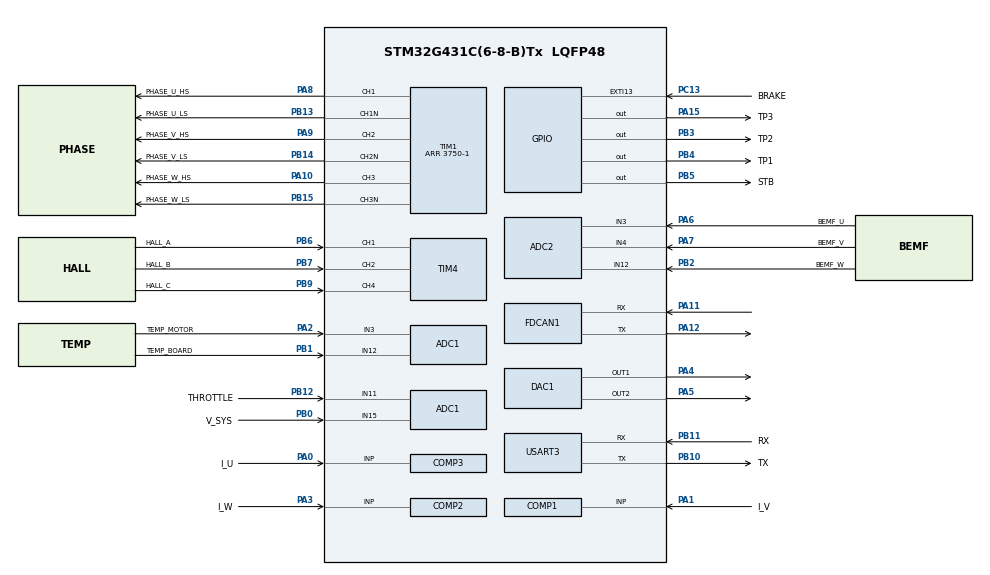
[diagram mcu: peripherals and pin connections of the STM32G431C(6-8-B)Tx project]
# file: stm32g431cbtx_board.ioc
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ADC1.Channel-0\#ChannelRegularConversion=ADC_CHANNEL_1
ADC1.Channel-1\#ChannelRegularConversion=ADC_CHANNEL_2
ADC1.Channel-2\#ChannelRegularConversion=ADC_CHANNEL_4
ADC1.Channel-3\#ChannelRegularConversion=ADC_CHANNEL_11
ADC1.Channel-4\#ChannelRegularConversion=ADC_CHANNEL_12
ADC1.Channel-5\#ChannelRegularConversion=ADC_CHANNEL_15
ADC1.Channel-6\#ChannelRegularConversion=ADC_CHANNEL_3
ADC1.ClockPrescaler=ADC_CLOCK_SYNC_PCLK_DIV4
ADC1.DMAContinuousRequests=ENABLE
ADC1.ExternalTrigConv=ADC_EXTERNALTRIG_T1_TRGO
ADC1.ExternalTrigConvEdge=ADC_EXTERNALTRIGCONVEDGE_FALLING
ADC1.NbrOfConversion=7
ADC1.NbrOfConversionFlag=1
ADC1.OffsetNumber-0\#ChannelRegularConversion=ADC_OFFSET_NONE
ADC1.OffsetNumber-1\#ChannelRegularConversion=ADC_OFFSET_NONE
ADC1.OffsetNumber-2\#ChannelRegularConversion=ADC_OFFSET_NONE
ADC1.OffsetNumber-3\#ChannelRegularConversion=ADC_OFFSET_NONE
ADC1.OffsetNumber-4\#ChannelRegularConversion=ADC_OFFSET_NONE
ADC1.OffsetNumber-5\#ChannelRegularConversion=ADC_OFFSET_NONE
ADC1.OffsetNumber-6\#ChannelRegularConversion=ADC_OFFSET_NONE
ADC1.Rank-0\#ChannelRegularConversion=1
ADC1.Rank-1\#ChannelRegularConversion=2
ADC1.Rank-2\#ChannelRegularConversion=3
ADC1.Rank-3\#ChannelRegularConversion=4
ADC1.Rank-4\#ChannelRegularConversion=5
ADC1.Rank-5\#ChannelRegularConversion=6
ADC1.Rank-6\#ChannelRegularConversion=7
ADC1.SamplingTime-0\#ChannelRegularConversion=ADC_SAMPLETIME_6CYCLES_5
ADC1.SamplingTime-1\#ChannelRegularConversion=ADC_SAMPLETIME_6CYCLES_5
ADC1.SamplingTime-2\#ChannelRegularConversion=ADC_SAMPLETIME_6CYCLES_5
ADC1.SamplingTime-3\#ChannelRegularConversion=ADC_SAMPLETIME_6CYCLES_5
ADC1.SamplingTime-4\#ChannelRegularConversion=ADC_SAMPLETIME_6CYCLES_5
ADC1.SamplingTime-5\#ChannelRegularConversion=ADC_SAMPLETIME_6CYCLES_5
ADC1.SamplingTime-6\#ChannelRegularConversion=ADC_SAMPLETIME_6CYCLES_5
ADC1.master=1
ADC2.Channel-0\#ChannelRegularConversion=ADC_CHANNEL_3
ADC2.ClockPrescaler=ADC_CLOCK_SYNC_PCLK_DIV4
ADC2.NbrOfConversionFlag=1
ADC2.OffsetNumber-0\#ChannelRegularConversion=ADC_OFFSET_NONE
ADC2.Rank-0\#ChannelRegularConversion=1
ADC2.SamplingTime-0\#ChannelRegularConversion=ADC_SAMPLETIME_2CYCLES_5
DAC1.DAC_Channel-DAC_OUT2_ExtAndInt=DAC_CHANNEL_2
DAC3.DAC_Channel-DAC_OUT2_Int=DAC_CHANNEL_2
Dma.ADC1.0.Direction=DMA_PERIPH_TO_MEMORY
Dma.ADC1.0.EventEnable=DISABLE
Dma.ADC1.0.Instance=DMA1_Channel1
Dma.ADC1.0.MemDataAlignment=DMA_MDATAALIGN_WORD
Dma.ADC1.0.MemInc=DMA_MINC_ENABLE
Dma.ADC1.0.Mode=DMA_CIRCULAR
Dma.ADC1.0.PeriphDataAlignment=DMA_PDATAALIGN_WORD
Dma.ADC1.0.PeriphInc=DMA_PINC_DISABLE
Dma.ADC1.0.Polarity=HAL_DMAMUX_REQ_GEN_RISING
Dma.ADC1.0.Priority=DMA_PRIORITY_LOW
Dma.ADC1.0.RequestNumber=1
Dma.ADC1.0.SignalID=NONE
Dma.ADC1.0.SyncEnable=DISABLE
Dma.ADC1.0.SyncPolarity=HAL_DMAMUX_SYNC_NO_EVENT
Dma.ADC1.0.SyncRequestNumber=1
Dma.ADC1.0.SyncSignalID=NONE
Dma.Request0=ADC1
FDCAN1.AutoRetransmission=ENABLE
FDCAN1.NominalPrescaler=20
FDCAN1.NominalTimeSeg1=12
FDCAN1.StdFiltersNbr=1
FDCAN1.TransmitPause=ENABLE
Mcu.Family=STM32G4
Mcu.Name=STM32G431C(6-8-B)Tx
Mcu.Package=LQFP48
NVIC.DMA1_Channel1_IRQn=true\:0\:0\:false\:false\:true\:false\:true\:true
NVIC.EXTI15_10_IRQn=true\:0\:0\:false\:false\:false\:true\:false\:true
NVIC.FDCAN1_IT0_IRQn=true\:0\:0\:false\:false\:true\:true\:true\:true
NVIC.PriorityGroup=NVIC_PRIORITYGROUP_4
NVIC.TIM1_BRK_TIM15_IRQn=true\:0\:0\:false\:false\:false\:true\:true\:true
NVIC.TIM2_IRQn=true\:0\:0\:false\:false\:false\:true\:true\:true
NVIC.TIM3_IRQn=true\:0\:0\:false\:false\:false\:true\:true\:true
NVIC.TIM4_IRQn=true\:0\:0\:false\:false\:false\:true\:true\:true
NVIC.TIM8_UP_IRQn=true\:0\:0\:false\:false\:false\:true\:true\:true
PA0.GPIO_Label=I_U
PA0.Signal=SharedAnalog_PA0
PA1.GPIO_Label=I_V
PA1.Signal=SharedAnalog_PA1
PA10.GPIO_Label=PHASE_W_HS
PA10.Signal=S_TIM1_CH3
PA11.Mode=FDCAN_Activate
PA11.Signal=FDCAN1_RX
PA12.Mode=FDCAN_Activate
PA12.Signal=FDCAN1_TX
PA13.Mode=Serial_Wire
PA13.Signal=SYS_JTMS-SWDIO
PA14.Mode=Serial_Wire
PA14.Signal=SYS_JTCK-SWCLK
PA15.GPIO_Label=TP3
PA15.GPIO_Speed=GPIO_SPEED_FREQ_VERY_HIGH
PA15.Signal=GPIO_Output
PA2.GPIO_Label=TEMP_MOTOR
PA2.Mode=IN3-Single-Ended
PA2.Signal=ADC1_IN3
PA3.GPIO_Label=I_W
PA3.Signal=SharedAnalog_PA3
PA4.Signal=COMP_DAC11_group
PA5.Signal=COMP_DAC12_group
PA6.GPIO_Label=BEMF_U
PA6.Mode=IN3-Single-Ended
PA6.Signal=ADC2_IN3
PA7.GPIO_Label=BEMF_V
PA7.Mode=IN4-Single-Ended
PA7.Signal=ADC2_IN4
PA8.GPIO_Label=PHASE_U_HS
PA8.Signal=S_TIM1_CH1
PA9.GPIO_Label=PHASE_V_HS
PA9.Signal=S_TIM1_CH2
PB0.GPIO_Label=V_SYS
PB0.Signal=SharedAnalog_PB0
PB1.GPIO_Label=TEMP_BOARD
PB1.Mode=IN12-Single-Ended
PB1.Signal=ADC1_IN12
PB10.GPIO_Label=TX
PB10.Mode=Asynchronous
PB10.Signal=USART3_TX
PB11.GPIO_Label=RX
PB11.Mode=Asynchronous
PB11.Signal=USART3_RX
PB12.GPIO_Label=THROTTLE
PB12.Mode=IN11-Single-Ended
PB12.Signal=ADC1_IN11
PB13.GPIO_Label=PHASE_U_LS
PB13.Mode=PWM Generation1 CH1 CH1N
PB13.Signal=TIM1_CH1N
PB14.GPIO_Label=PHASE_V_LS
PB14.Mode=PWM Generation2 CH2 CH2N
PB14.Signal=TIM1_CH2N
PB15.GPIO_Label=PHASE_W_LS
PB15.Mode=PWM Generation3 CH3 CH3N
PB15.Signal=TIM1_CH3N
PB2.GPIO_Label=BEMF_W
PB2.Mode=IN12-Single-Ended
PB2.Signal=ADC2_IN12
PB3.GPIO_Label=TP2
PB3.GPIO_Speed=GPIO_SPEED_FREQ_VERY_HIGH
PB3.Signal=GPIO_Output
PB4.GPIO_Label=TP1
PB4.GPIO_Speed=GPIO_SPEED_FREQ_VERY_HIGH
PB4.Signal=GPIO_Output
PB5.GPIO_Label=STB
PB5.Signal=GPIO_Output
PB6.GPIO_Label=HALL_A
PB6.Signal=S_TIM4_CH1
PB7.GPIO_Label=HALL_B
PB7.Signal=S_TIM4_CH2
PB9.GPIO_Label=HALL_C
PB9.Signal=S_TIM4_CH4
PC13.GPIO_Label=BRAKE
PC13.GPIO_ModeDefaultEXTI=GPIO_MODE_IT_RISING_FALLING
PC13.Signal=GPXTI13
PF0-OSC_IN.Mode=HSE-External-Oscillator
PF0-OSC_IN.Signal=RCC_OSC_IN
PF1-OSC_OUT.Mode=HSE-External-Oscillator
PF1-OSC_OUT.Signal=RCC_OSC_OUT
ProjectManager.HeapSize=0x200
ProjectManager.StackSize=0x400
ProjectManager.TargetToolchain=STM32CubeIDE
RCC.ADC12Freq_Value=150000000
RCC.AHBFreq_Value=150000000
RCC.APB1Freq_Value=150000000
RCC.APB1TimFreq_Value=150000000
RCC.APB2Freq_Value=150000000
RCC.APB2TimFreq_Value=150000000
RCC.CortexFreq_Value=150000000
RCC.EXTERNAL_CLOCK_VALUE=12288000
RCC.HCLKFreq_Value=150000000
RCC.HSE_VALUE=12000000
RCC.HSI48_VALUE=48000000
RCC.HSI_VALUE=16000000
RCC.LSE_VALUE=32768
RCC.PLLN=25
RCC.PLLSourceVirtual=RCC_PLLSOURCE_HSE
RCC.SYSCLKFreq_VALUE=150000000
RCC.SYSCLKSource=RCC_SYSCLKSOURCE_PLLCLK
RCC.USBFreq_Value=150000000
RCC.VCOOutputFreq_Value=300000000
SH.COMP_DAC11_group.0=DAC1_OUT1,DAC_OUT1_ExtAndInt
SH.COMP_DAC12_group.0=DAC1_OUT2,DAC_OUT2_ExtAndInt
SH.S_TIM1_CH1.0=TIM1_CH1,PWM Generation1 CH1 CH1N
SH.S_TIM1_CH2.0=TIM1_CH2,PWM Generation2 CH2 CH2N
SH.S_TIM1_CH3.0=TIM1_CH3,PWM Generation3 CH3 CH3N
SH.S_TIM4_CH1.0=TIM4_CH1,Input_Capture1_from_TI1
SH.S_TIM4_CH2.0=TIM4_CH2,Input_Capture2_from_TI2
SH.S_TIM4_CH4.0=TIM4_CH4,Input_Capture4_from_TI4
SH.SharedAnalog_PA0.0=COMP3_INP,INP
SH.SharedAnalog_PA0.1=ADC1_IN1,IN1-Single-Ended
SH.SharedAnalog_PA1.0=COMP1_INP,INP
SH.SharedAnalog_PA1.1=ADC1_IN2,IN2-Single-Ended
SH.SharedAnalog_PA3.0=COMP2_INP,INP
SH.SharedAnalog_PA3.1=ADC1_IN4,IN4-Single-Ended
SH.SharedAnalog_PB0.0=COMP4_INP
SH.SharedAnalog_PB0.1=ADC1_IN15,IN15-Single-Ended
TIM1.AutoReloadPreload=TIM_AUTORELOAD_PRELOAD_ENABLE
TIM1.Break2State=TIM_BREAK2_ENABLE
TIM1.Channel-PWM\ Generation1\ CH1\ CH1N=TIM_CHANNEL_1
TIM1.Channel-PWM\ Generation2\ CH2\ CH2N=TIM_CHANNEL_2
TIM1.Channel-PWM\ Generation3\ CH3\ CH3N=TIM_CHANNEL_3
TIM1.Channel-PWM\ Generation4\ No\ Output=TIM_CHANNEL_4
TIM1.CounterMode=TIM_COUNTERMODE_CENTERALIGNED3
TIM1.DeadTime=60
TIM1.DeadTimePreload=ENABLE
TIM1.OffStateIDLEMode=TIM_OSSI_ENABLE
TIM1.OffStateRunMode=TIM_OSSR_ENABLE
TIM1.PeriodNoDither=3750-1
TIM1.SourceBRK2COMP1=TIM_BREAKINPUTSOURCE_ENABLE
TIM1.SourceBRK2COMP2=TIM_BREAKINPUTSOURCE_ENABLE
TIM1.SourceBRK2COMP3=TIM_BREAKINPUTSOURCE_ENABLE
TIM1.TIM_MasterOutputTrigger=TIM_TRGO_OC4REF
TIM1.TIM_MasterSlaveMode=TIM_MASTERSLAVEMODE_ENABLE
TIM2.Prescaler=1023
TIM3.PeriodNoDither=10000
TIM3.Prescaler=1499
TIM4.Channel-Input_Capture1_from_TI1=TIM_CHANNEL_1
TIM4.Channel-Input_Capture2_from_TI2=TIM_CHANNEL_2
TIM4.Channel-Input_Capture4_from_TI4=TIM_CHANNEL_4
TIM4.ICPolarity_CH1=TIM_INPUTCHANNELPOLARITY_BOTHEDGE
TIM4.ICPolarity_CH2=TIM_INPUTCHANNELPOLARITY_BOTHEDGE
TIM4.ICPolarity_CH4=TIM_INPUTCHANNELPOLARITY_BOTHEDGE
TIM8.PeriodNoDither=1000
TIM8.Prescaler=150
USART3.VirtualMode-Asynchronous=VM_ASYNC
VP_COMP1_VS_DAC3OUT1.Mode=INM_DAC3OUT1
VP_COMP2_VS_DAC3OUT2.Mode=INM_DAC3OUT2
VP_COMP3_VS_DAC3OUT1.Mode=INM_DAC3OUT1
VP_DAC3_VS_DACI1.Mode=DAC_OUT1_Int
VP_DAC3_VS_DACI2.Mode=DAC_OUT2_Int
VP_SYS_VS_DBSignals.Mode=DisableDeadBatterySignals
VP_SYS_V_VREFBUF.Mode=ExternalMode
VP_TIM1_VS_ClockSourceINT.Mode=Internal
VP_TIM1_VS_no_output4.Mode=PWM Generation4 No Output
VP_TIM2_VS_ClockSourceINT.Mode=Internal
VP_TIM3_VS_ClockSourceINT.Mode=Internal
VP_TIM8_VS_ClockSourceINT.Mode=Internal
board=custom

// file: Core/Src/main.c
/* USER CODE BEGIN Header */
/**
  ******************************************************************************
  * @file           : main.c
  * @brief          : Main program body
  ******************************************************************************
  * @attention
  *
  * Copyright (c) 2023 STMicroelectronics.
  * All rights reserved.
  *
  * This software is licensed under terms that can be found in the LICENSE file
  * in the root directory of this software component.
  * If no LICENSE file comes with this software, it is provided AS-IS.
  *
  ******************************************************************************
  */
/* USER CODE END Header */
#include "main.h"
#include "adc.h"
#include "comp.h"
#include "dac.h"
#include "dma.h"
#include "fdcan.h"
#include "tim.h"
#include "usart.h"
#include "gpio.h"

#define FREQ_PWM_HZ	20000UL //20khz
#define DEAD_TIME_NS	400 //400ns

uint32_t adc_values[7];
float throttle_adc = 0;
uint32_t duty = 0;

void SystemClock_Config(void);

void set_deadtime_pwm_ns(uint32_t time_ns);
void set_duty_pwm(float duty);
void set_freq_pwm(uint32_t freq);
float get_duty_value();
void update_1khz(void);

int main(void)
{

  /* MCU Configuration--------------------------------------------------------*/

  /* Reset of all peripherals, Initializes the Flash interface and the Systick. */
  HAL_Init();

  /* Configure the system clock */
  SystemClock_Config();

  /* Initialize all configured peripherals */
  MX_GPIO_Init();
  MX_DMA_Init();
  MX_ADC2_Init();
  MX_COMP1_Init();
  MX_COMP2_Init();
  MX_COMP3_Init();
  MX_ADC1_Init();
  MX_DAC1_Init();
  MX_DAC3_Init();
  MX_FDCAN1_Init();
  MX_TIM1_Init();
  MX_TIM2_Init();
  MX_TIM3_Init();
  MX_TIM4_Init();
  MX_TIM8_Init();
  MX_USART3_UART_Init();
  /* USER CODE BEGIN 2 */

  update_1khz();

  /* USER CODE END 2 */

  /* Infinite loop */
  while (1)
  {

  }
}

 void TIM8_UP_IRQHandler(void){

	get_duty_value();
	set_freq_pwm(FREQ_PWM_HZ);
	set_deadtime_pwm_ns(DEAD_TIME_NS);
	set_duty_pwm(duty);
	LL_TIM_ClearFlag_UPDATE(TIM8);
}

void update_1khz(void){

	LL_TIM_EnableIT_UPDATE(TIM8);
	LL_TIM_EnableCounter(TIM8);

}

float get_duty_value(){

	if(HAL_ADC_Start_DMA(&hadc1, (uint32_t *)adc_values, 7)== HAL_OK){

		throttle_adc = adc_values[3] / 4095.0f ;
	}

	duty = (throttle_adc *TIM1->ARR);
	return duty ;
}
//WRITE_REG(TIMx->CCR1, CompareValue);

void set_freq_pwm(uint32_t freq){

	uint32_t result = 0;
	result = (HAL_RCC_GetPCLK2Freq() / freq /2 );
	TIM1->ARR = result;
}

void set_deadtime_pwm_ns(uint32_t time_ns){

	uint32_t time_s = time_ns / 1000000000UL ;
	uint32_t result = 0;
	result = (time_s * HAL_RCC_GetPCLK2Freq());
	MODIFY_REG(TIM1->BDTR, TIM_BDTR_DTG, result);
}

void set_duty_pwm(float duty){

	LL_TIM_DisableAllOutputs(TIM1);
	TIM1->CCR1 = duty ;
	TIM1->CCR2 = duty ;
	TIM1->CCR3 = duty ;
	LL_TIM_EnableAllOutputs(TIM1);
}

void SystemClock_Config(void)
{
  LL_FLASH_SetLatency(LL_FLASH_LATENCY_4);
  while(LL_FLASH_GetLatency() != LL_FLASH_LATENCY_4)
  {
  }
  LL_PWR_SetRegulVoltageScaling(LL_PWR_REGU_VOLTAGE_SCALE1);
  LL_RCC_HSE_Enable();
   /* Wait till HSE is ready */
  while(LL_RCC_HSE_IsReady() != 1)
  {
  }

  LL_RCC_PLL_ConfigDomain_SYS(LL_RCC_PLLSOURCE_HSE, LL_RCC_PLLM_DIV_1, 25, LL_RCC_PLLR_DIV_2);
  LL_RCC_PLL_EnableDomain_SYS();
  LL_RCC_PLL_Enable();
   /* Wait till PLL is ready */
  while(LL_RCC_PLL_IsReady() != 1)
  {
  }

  LL_RCC_SetSysClkSource(LL_RCC_SYS_CLKSOURCE_PLL);
  LL_RCC_SetAHBPrescaler(LL_RCC_SYSCLK_DIV_2);
   /* Wait till System clock is ready */
  while(LL_RCC_GetSysClkSource() != LL_RCC_SYS_CLKSOURCE_STATUS_PLL)
  {
  }

  /* Insure 1�s transition state at intermediate medium speed clock based on DWT */
  CoreDebug->DEMCR |= CoreDebug_DEMCR_TRCENA_Msk;
  DWT->CTRL |= DWT_CTRL_CYCCNTENA_Msk;
  DWT->CYCCNT = 0;
  while(DWT->CYCCNT < 100);
  /* Set AHB prescaler*/
  LL_RCC_SetAHBPrescaler(LL_RCC_SYSCLK_DIV_1);
  LL_RCC_SetAPB1Prescaler(LL_RCC_APB1_DIV_1);
  LL_RCC_SetAPB2Prescaler(LL_RCC_APB2_DIV_1);
  LL_SetSystemCoreClock(150000000);

   /* Update the time base */
  if (HAL_InitTick (TICK_INT_PRIORITY) != HAL_OK)
  {
    Error_Handler();
  }
}

void Error_Handler(void)
{
  __disable_irq();
  while (1)
  {
  }
}
